# STM32F207xx register map
File version: 1.0
Registers are 32-bit, read-write, reset 0x0 unless marked. A register's access mark holds for its fields unless they carry their own. Offsets are from the block's base; [hi:lo] are bit positions.

## SPI2 — Serial Peripheral Interface
Base 0x40003800
Same registers: SPI3 0x40003C00, SPI1 0x40013000
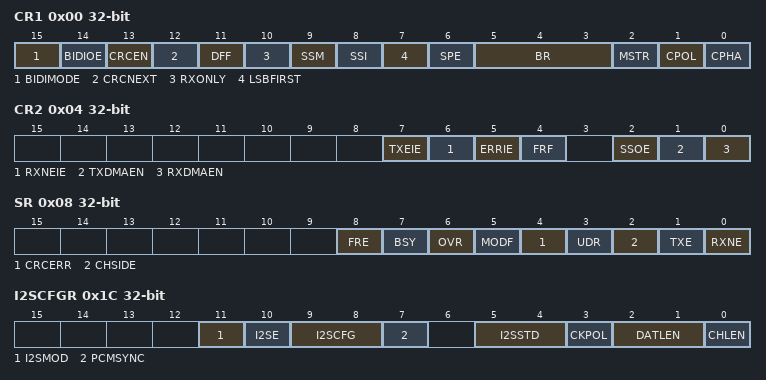
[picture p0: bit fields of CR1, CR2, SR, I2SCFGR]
0x00 CR1 — SPI control register 1 (not used in I2S mode)
  [15] BIDIMODE — Bidirectional data mode enable
  [14] BIDIOE — Output enable in bidirectional mode
  [13] CRCEN — Hardware CRC calculation enable
  [12] CRCNEXT — Transmit CRC next
  [11] DFF — Data Frame Format
    0=DATAWIDTH_8BIT (Data length for SPI transfer: 8 bits); 1=DATAWIDTH_16BIT (Data length for SPI transfer: 16 bits)
  [10] RXONLY — Receive only
  [9] SSM — Software slave management
  [8] SSI — Internal slave select
  [7] LSBFIRST — Frame Format
    1=LSB_FIRST (Data is transmitted/received with the LSB first); 0=MSB_FIRST (Data is transmitted/received with the MSB first)
  [6] SPE — SPI Enable
  [5:3] BR — BR[2:0] bits (Baud Rate Control)
    0=DIV2 (BaudRate control equal to fPCLK/2); 1=DIV4 (BaudRate control equal to fPCLK/4); 2=DIV8 (BaudRate control equal to fPCLK/8); 3=DIV16 (BaudRate control equal to fPCLK/16); 4=DIV32 (BaudRate control equal to fPCLK/32); 5=DIV64 (BaudRate control equal to fPCLK/64); 6=DIV128 (BaudRate control equal to fPCLK/128); 7=DIV256 (BaudRate control equal to fPCLK/256)
  [2] MSTR — Master Selection
  [1] CPOL — Clock Polarity
    0=LOW (Clock to 0 when idle); 1=HIGH (Clock to 1 when idle)
  [0] CPHA — Clock Phase
    0=PHASE_1EDGE (First clock transition is the first data capture edge); 1=PHASE_2EDGE (Second clock transition is the first data capture edge)
0x04 CR2 — SPI control register 2
  [7] TXEIE — Tx buffer Empty Interrupt Enable
  [6] RXNEIE — RX buffer Not Empty Interrupt Enable
  [5] ERRIE — Error Interrupt Enable
  [4] FRF — Frame Format
    0=MOTOROLA (Motorola mode. Used as default value); 1=TI (TI mode)
  [2] SSOE — SS Output Enable
  [1] TXDMAEN — Tx Buffer DMA Enable
  [0] RXDMAEN — Rx Buffer DMA Enable
0x08 SR — SPI status register
  [8] FRE — Frame format error flag
  [7] BSY — Busy flag
  [6] OVR — Overrun flag
  [5] MODF — Mode fault
  [4] CRCERR — CRC Error flag
  [3] UDR — Underrun flag
  [2] CHSIDE — Channel side
  [1] TXE — Transmit buffer Empty
  [0] RXNE — Receive buffer Not Empty
0x0C DR — SPI data register
  [15:0] DR — Data Register
0x10 CRCPR — SPI CRC polynomial register (not used in I2S mode)
  [15:0] CRCPOLY — CRC polynomial register
0x14 RXCRCR — SPI RX CRC register (not used in I2S mode)
  [15:0] RXCRC
0x18 TXCRCR — SPI TX CRC register (not used in I2S mode)
  [15:0] TXCRC
0x1C I2SCFGR — SPI_I2S configuration register
  [11] I2SMOD — I2S mode selection
  [10] I2SE — I2S Enable
  [9:8] I2SCFG — I2SCFG[1:0] bits (I2S configuration mode)
    0=SLAVE_TX (Slave Tx configuration); 1=SLAVE_RX (Slave Rx configuration); 2=MASTER_TX (Master Tx configuration); 3=MASTER_RX (Master Rx configuration)
  [7] PCMSYNC — PCM frame synchronization
  [5:4] I2SSTD — I2SSTD[1:0] bits (I2S standard selection)
  [3] CKPOL — steady state clock polarity
    0=LOW (Clock steady state is low level); 1=HIGH (Clock steady state is high level)
  [2:1] DATLEN — DATLEN[1:0] bits (Data length to be transferred)
  [0] CHLEN — Channel length (number of bits per audio channel)
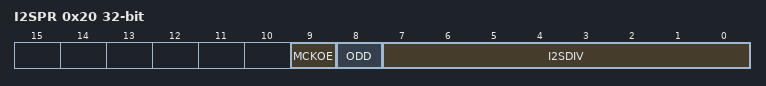
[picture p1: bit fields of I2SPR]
0x20 I2SPR — SPI_I2S prescaler register
  [9] MCKOE — Master Clock Output Enable
  [8] ODD — Odd factor for the prescaler
  [7:0] I2SDIV — I2S Linear prescaler

## USART2 — Universal Synchronous Asynchronous Receiver Transmitter
Base 0x40004400
Same registers: USART3 0x40004800, USART1 0x40011000, USART6 0x40011400
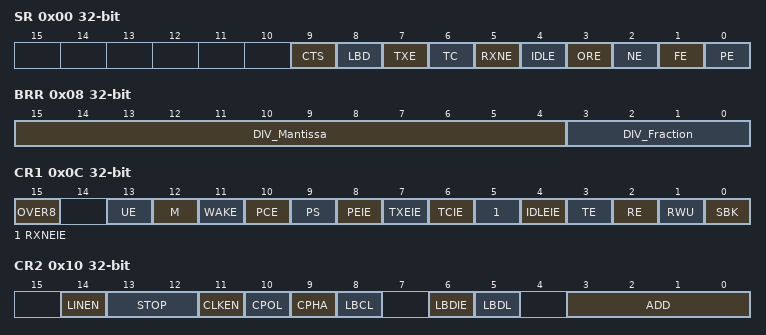
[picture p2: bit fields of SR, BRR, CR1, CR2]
0x00 SR — USART Status register
  [9] CTS — CTS Flag
  [8] LBD — LIN Break Detection Flag
  [7] TXE — Transmit Data Register Empty
  [6] TC — Transmission Complete
  [5] RXNE — Read Data Register Not Empty
  [4] IDLE — IDLE line detected
  [3] ORE — OverRun Error
  [2] NE — Noise Error Flag
  [1] FE — Framing Error
  [0] PE — Parity Error
0x04 DR — USART Data register
  [8:0] DR — Data value
0x08 BRR — USART Baud rate register
  [15:4] DIV_Mantissa — Mantissa of USARTDIV
  [3:0] DIV_Fraction — Fraction of USARTDIV
0x0C CR1 — USART Control register 1
  [15] OVER8 — USART Oversampling by 8 enable
    0=OVERSAMPLING_16 (Oversampling by 16); 1=OVERSAMPLING_8 (Oversampling by 8)
  [13] UE — USART Enable
  [12] M — Word length
    0=DATAWIDTH_8B (8 bits word length : Start bit, 8 data bits, n stop bits); 1=DATAWIDTH_9B (9 bits word length : Start bit, 9 data bits, n stop bits)
  [11] WAKE — Wakeup method
    0=IDLELINE (USART wake up from Mute mode on Idle Line); 1=ADDRESSMARK (USART wake up from Mute mode on Address Mark)
  [10] PCE — Parity Control Enable
  [9] PS — Parity Selection
  [8] PEIE — PE Interrupt Enable
  [7] TXEIE — PE Interrupt Enable
  [6] TCIE — Transmission Complete Interrupt Enable
  [5] RXNEIE — RXNE Interrupt Enable
  [4] IDLEIE — IDLE Interrupt Enable
  [3] TE — Transmitter Enable
  [2] RE — Receiver Enable
  [1] RWU — Receiver wakeup
  [0] SBK — Send Break
0x10 CR2 — USART Control register 2
  [14] LINEN — LIN mode enable
  [13:12] STOP — STOP[1:0] bits (STOP bits)
    1=STOPBITS_0_5 (0.5 stop bit); 0=STOPBITS_1 (1 stop bit); 3=STOPBITS_1_5 (1.5 stop bits); 2=STOPBITS_2 (2 stop bits)
  [11] CLKEN — Clock Enable
  [10] CPOL — Clock Polarity
    0=LOW (Steady low value on SCLK pin outside transmission window); 1=HIGH (Steady high value on SCLK pin outside transmission window)
  [9] CPHA — Clock Phase
    0=PHASE_1EDGE (The first clock transition is the first data capture edge); 1=PHASE_2EDGE (The second clock transition is the first data capture edge)
  [8] LBCL — Last Bit Clock pulse
    0=NO_OUTPUT (The clock pulse of the last data bit is not output to the SCLK pin); 1=OUTPUT (The clock pulse of the last data bit is output to the SCLK pin)
  [6] LBDIE — LIN Break Detection Interrupt Enable
  [5] LBDL — LIN Break Detection Length
    0=DETECT_10B (10-bit break detection method selected); 1=DETECT_11B (11-bit break detection method selected)
  [3:0] ADD — Address of the USART node
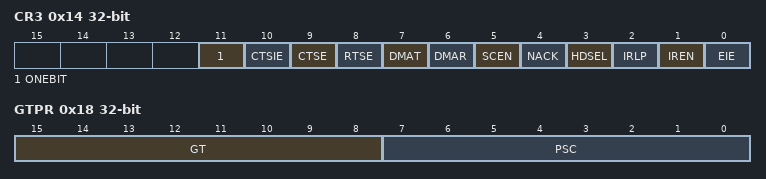
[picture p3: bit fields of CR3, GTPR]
0x14 CR3 — USART Control register 3
  [11] ONEBIT — USART One bit method enable
  [10] CTSIE — CTS Interrupt Enable
  [9] CTSE — CTS Enable
  [8] RTSE — RTS Enable
  [7] DMAT — DMA Enable Transmitter
  [6] DMAR — DMA Enable Receiver
  [5] SCEN — Smartcard mode enable
  [4] NACK — Smartcard NACK enable
  [3] HDSEL — Half-Duplex Selection
  [2] IRLP — IrDA Low-Power
    0=NORMAL (IrDA normal power mode); 1=LOW (IrDA low power mode)
  [1] IREN — IrDA mode Enable
  [0] EIE — Error Interrupt Enable
0x18 GTPR — USART Guard time and prescaler register
  [15:8] GT — Guard time value
  [7:0] PSC — PSC[7:0] bits (Prescaler value)
